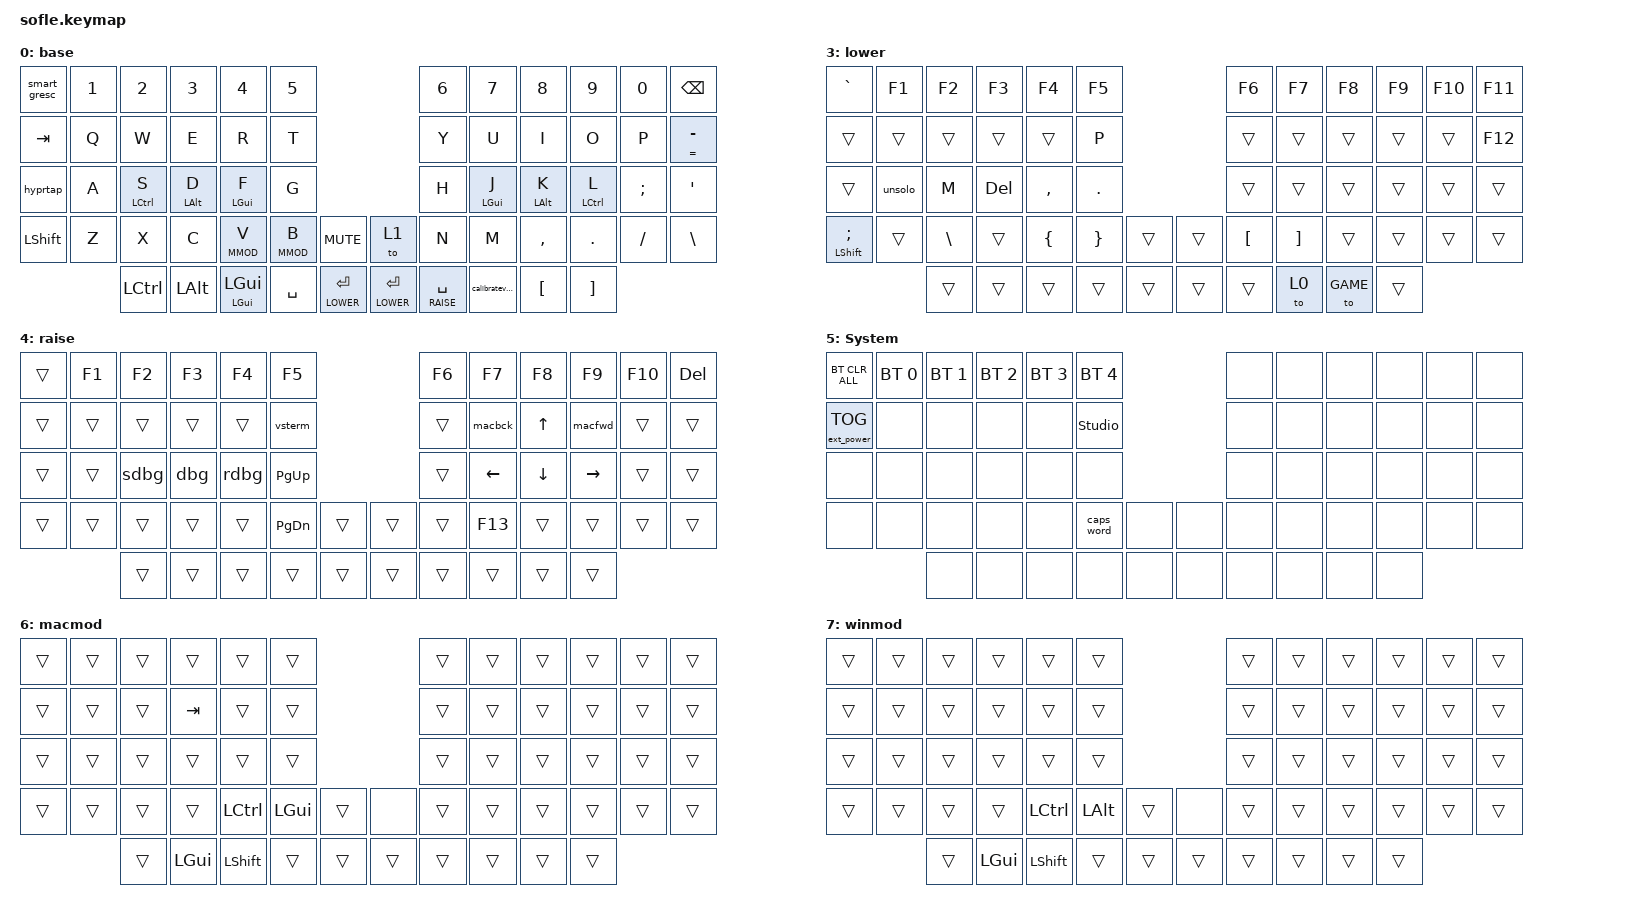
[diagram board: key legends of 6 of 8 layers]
/*
 * Copyright (c) 2020 The ZMK Contributors
 *
 * SPDX-License-Identifier: MIT
 */

#include <behaviors.dtsi>
#include <dt-bindings/zmk/bt.h>
#include <dt-bindings/zmk/ext_power.h>
#include <dt-bindings/zmk/keys.h>

// Encoders

&sensors { triggers-per-rotation = <30>; };

&left_encoder { steps = <60>; };

&right_encoder { steps = <60>; };

#define BASE 0
#define LOGIC 1
#define GAME 2
#define LOWER 3
#define RAISE 4
#define ADJUST 5
#define MMOD 6
#define WMOD 7

/ {
    // Activate ADJUST layer by pressing raise and lower

    conditional_layers {
        compatible = "zmk,conditional-layers";

        adjust_layer {
            if-layers = <LOWER RAISE>;
            then-layer = <ADJUST>;
        };
    };

    behaviors {
        th: taphold {
            compatible = "zmk,behavior-hold-tap";
            label = "TAP HOLD";
            #binding-cells = <2>;
            tapping-term-ms = <180>;
            quick-tap-ms = <120>;
            flavor = "tap-preferred";
            bindings = <&kp>, <&kp>;
        };

        pwr_tap: power_hold_tap {
            compatible = "zmk,behavior-hold-tap";
            label = "POWER_HOLD_TAP";
            #binding-cells = <2>;
            flavor = "hold-preferred";
            tapping-term-ms = <170>;
            bindings = <&pwr>, <&iterm>;
        };

        smart_gresc: smart_gresc {
            compatible = "zmk,behavior-mod-morph";
            label = "smart_gresc";
            #binding-cells = <0>;
            bindings = <&kp ESC>, <&sub_gresc>;

            mods = <(MOD_LGUI|MOD_LSFT)>;
            keep-mods = <(MOD_LGUI|MOD_LSFT)>;
        };

        sub_gresc: sub_gresc {
            compatible = "zmk,behavior-mod-morph";
            label = "sub_gresc";
            #binding-cells = <0>;
            bindings = <&kp GRAVE>, <&kp ESC>;

            mods = <(MOD_LALT|MOD_LCTL)>;
            keep-mods = <(MOD_LALT|MOD_LCTL)>;
        };

        slt: spacebar_layer_tap {
            compatible = "zmk,behavior-hold-tap";
            label = "SPACE_LAYER_TAP";
            #binding-cells = <2>;
            flavor = "tap-preferred";
            tapping-term-ms = <200>;
            quick-tap-ms = <125>;
            global-quick-tap;
            bindings = <&mo>, <&kp>;
        };

        tnpt: tab_numpad_tap {
            compatible = "zmk,behavior-hold-tap";
            label = "TAB_NUMPAD_TAP";
            #binding-cells = <2>;
            flavor = "tap-preferred";
            tapping-term-ms = <200>;
            quick-tap-ms = <135>;
            global-quick-tap;
            bindings = <&mo>, <&kp>;
        };

        hyprtap: hyper_tap_dance {
            compatible = "zmk,behavior-tap-dance";
            label = "HYPER_TAP_DANCE";
            #binding-cells = <0>;
            tapping-term-ms = <170>;
            bindings = <&hpr>, <&pwr_tap 0 0>;
        };

        glmt: gui_layer_mod_tap {
            compatible = "zmk,behavior-hold-tap";
            label = "GUI_LAYER_MOD_TAP";
            #binding-cells = <2>;
            flavor = "tap-preferred";
            tapping-term-ms = <200>;
            quick-tap-ms = <135>;
            global-quick-tap;
            bindings = <&glm>, <&kp>;
        };

        almt: alt_layer_mod_tap {
            compatible = "zmk,behavior-hold-tap";
            label = "ALT_LAYER_MOD_TAP";
            #binding-cells = <2>;
            flavor = "tap-preferred";
            tapping-term-ms = <200>;
            quick-tap-ms = <135>;
            global-quick-tap;
            bindings = <&alm>, <&kp>;
        };

        clmt: ctrl_layer_mod_tap {
            compatible = "zmk,behavior-hold-tap";
            label = "CTRL_LAYER_MOD_TAP";
            #binding-cells = <2>;
            flavor = "tap-preferred";
            tapping-term-ms = <200>;
            quick-tap-ms = <135>;
            global-quick-tap;
            bindings = <&clm>, <&kp>;
        };

        slmt: shft_layer_mod_tap {
            compatible = "zmk,behavior-hold-tap";
            label = "SHFT_LAYER_MOD_TAP";
            #binding-cells = <2>;
            flavor = "tap-preferred";
            tapping-term-ms = <200>;
            quick-tap-ms = <135>;
            global-quick-tap;
            bindings = <&slm>, <&kp>;
        };

        cmt: cust_mod_tap {
            compatible = "zmk,behavior-hold-tap";
            label = "CUST_MOD_TAP";
            #binding-cells = <2>;
            flavor = "tap-preferred";
            tapping-term-ms = <200>;
            quick-tap-ms = <135>;
            global-quick-tap;
            bindings = <&kp>, <&kp>;
        };
    };

    macros {
        hpr: hyper {
            label = "hyper";
            compatible = "zmk,behavior-macro";
            #binding-cells = <0>;
            wait-ms = <0>;
            bindings =
                <&macro_press>,
                <&kp LSHFT &kp LCTRL &kp LALT &kp LGUI>,
                <&macro_pause_for_release>,
                <&macro_release>,
                <&kp LSHFT &kp LCTRL &kp LALT &kp LGUI>;
        };

        pwr: powerclaw {
            label = "powerclaw";
            compatible = "zmk,behavior-macro";
            #binding-cells = <0>;
            wait-ms = <0>;
            bindings =
                <&macro_press>,
                <&kp LCTRL &kp LALT &kp LGUI>,
                <&macro_pause_for_release>,
                <&macro_release>,
                <&kp LCTRL &kp LALT &kp LGUI>;
        };

        meh: meh {
            label = "meh";
            compatible = "zmk,behavior-macro";
            #binding-cells = <0>;
            wait-ms = <0>;
            bindings =
                <&macro_press>,
                <&kp LSHFT &kp LCTRL &kp LALT &kp LGUI>,
                <&macro_pause_for_release>,
                <&macro_release>,
                <&kp LSHFT &kp LCTRL &kp LALT &kp LGUI>;
        };

        macbck: macbck {
            label = "macbck";
            compatible = "zmk,behavior-macro";
            #binding-cells = <0>;
            wait-ms = <10>;
            bindings =
                <&macro_press>,
                <&kp LGUI>,
                <&macro_tap>,
                <&kp LBKT>,
                <&macro_release>,
                <&kp LGUI>;
        };

        macfwd: macfwd {
            label = "macfwd";
            compatible = "zmk,behavior-macro";
            #binding-cells = <0>;
            wait-ms = <10>;
            bindings =
                <&macro_press>,
                <&kp LGUI>,
                <&macro_tap>,
                <&kp RBKT>,
                <&macro_release>,
                <&kp LGUI>;
        };

        iterm: iterm {
            label = "iterm";
            compatible = "zmk,behavior-macro";
            #binding-cells = <0>;
            wait-ms = <0>;
            bindings =
                <&macro_press>,
                <&kp LSHFT &kp LCTRL &kp LALT &kp LGUI>,
                <&macro_tap>,
                <&kp T>,
                <&macro_release>,
                <&kp LSHFT &kp LCTRL &kp LALT &kp LGUI>;
        };

        unsolo: unsolo {
            label = "unsolo";
            compatible = "zmk,behavior-macro";
            #binding-cells = <0>;
            wait-ms = <0>;
            bindings =
                <&macro_press>,
                <&kp LCTRL &kp LALT &kp LGUI>,
                <&macro_tap>,
                <&kp S>,
                <&macro_release>,
                <&kp LCTRL &kp LALT &kp LGUI>;
        };

        dbg: vscode_debug {
            label = "vscode_debug";
            compatible = "zmk,behavior-macro";
            #binding-cells = <0>;
            wait-ms = <0>;
            bindings = <&macro_tap>, <&kp F5>;
        };

        rdbg: restart_debug {
            label = "restart_debug";
            compatible = "zmk,behavior-macro";
            #binding-cells = <0>;
            wait-ms = <0>;
            bindings =
                <&macro_press>,
                <&kp LSHFT &kp LGUI>,
                <&macro_tap>,
                <&kp F5>,
                <&macro_release>,
                <&kp LSHFT &kp LGUI>;
        };

        sdbg: stop_debug {
            label = "stop_debug";
            compatible = "zmk,behavior-macro";
            #binding-cells = <0>;
            wait-ms = <0>;
            bindings =
                <&macro_press>,
                <&kp LSHFT>,
                <&macro_tap>,
                <&kp F5>,
                <&macro_release>,
                <&kp LSHFT>;
        };

        vsterm: vscode_terminal {
            label = "vscode_terminal";
            compatible = "zmk,behavior-macro";
            #binding-cells = <0>;
            wait-ms = <0>;
            bindings =
                <&macro_press>,
                <&kp LCTRL>,
                <&macro_tap>,
                <&kp GRAVE>,
                <&macro_release>,
                <&kp LCTRL>;
        };

        glm: glm {
            label = "GUI_LAYER_MOD";
            compatible = "zmk,behavior-macro-one-param";
            wait-ms = <0>;
            tap-ms = <0>;
            #binding-cells = <1>;
            bindings =
                <&macro_param_1to1>,
                <&macro_press>,
                <&mo MACRO_PLACEHOLDER>,
                <&macro_press>,
                <&kp LGUI>,
                <&macro_pause_for_release>,
                <&macro_param_1to1>,
                <&macro_release>,
                <&mo MACRO_PLACEHOLDER>,
                <&macro_release>,
                <&kp LGUI>;
        };

        alm: alm {
            label = "ALT_LAYER_MOD";
            compatible = "zmk,behavior-macro-one-param";
            wait-ms = <0>;
            tap-ms = <0>;
            #binding-cells = <1>;
            bindings =
                <&macro_param_1to1>,
                <&macro_press>,
                <&mo MACRO_PLACEHOLDER>,
                <&macro_press>,
                <&kp LALT>,
                <&macro_pause_for_release>,
                <&macro_param_1to1>,
                <&macro_release>,
                <&mo MACRO_PLACEHOLDER>,
                <&macro_release>,
                <&kp LALT>;
        };

        clm: clm {
            label = "CTRL_LAYER_MOD";
            compatible = "zmk,behavior-macro-one-param";
            wait-ms = <0>;
            tap-ms = <0>;
            #binding-cells = <1>;
            bindings =
                <&macro_param_1to1>,
                <&macro_press>,
                <&mo MACRO_PLACEHOLDER>,
                <&macro_press>,
                <&kp LCTRL>,
                <&macro_pause_for_release>,
                <&macro_param_1to1>,
                <&macro_release>,
                <&mo MACRO_PLACEHOLDER>,
                <&macro_release>,
                <&kp LCTRL>;
        };

        slm: slm {
            label = "SHFT_LAYER_MOD";
            compatible = "zmk,behavior-macro-one-param";
            wait-ms = <0>;
            tap-ms = <0>;
            #binding-cells = <1>;
            bindings =
                <&macro_param_1to1>,
                <&macro_press>,
                <&mo MACRO_PLACEHOLDER>,
                <&macro_press>,
                <&kp LSHFT>,
                <&macro_pause_for_release>,
                <&macro_param_1to1>,
                <&macro_release>,
                <&mo MACRO_PLACEHOLDER>,
                <&macro_release>,
                <&kp LSHFT>;
        };

        shiftcomma: shiftcomma {
            compatible = "zmk,behavior-macro";
            label = "SHIFTCOMMA";
            #binding-cells = <0>;
            wait-ms = <0>;
            bindings =
                <&macro_press>,
                <&kp LEFT_SHIFT>,
                <&macro_tap>,
                <&kp COMMA>,
                <&macro_release>,
                <&kp LEFT_SHIFT>;
        };

        shiftdot: shiftdot {
            compatible = "zmk,behavior-macro";
            label = "SHIFTDOT";
            #binding-cells = <0>;
            wait-ms = <0>;
            bindings =
                <&macro_press>,
                <&kp LEFT_SHIFT>,
                <&macro_tap>,
                <&kp PERIOD>,
                <&macro_release>,
                <&kp LEFT_SHIFT>;
        };

        calibrateview: calibrateview {
            compatible = "zmk,behavior-macro";
            #binding-cells = <0>;
            bindings = <&macro_press>, <&kp LC(LA(LG(C)))>, <&macro_release>;

            label = "CALIBRATEVIEW";
        };
    };

    keymap {
        compatible = "zmk,keymap";

        default_layer {
            label = "base";
            display-name = "base";
            bindings = <
&smart_gresc  &kp N1  &kp N2        &kp N3       &kp N4          &kp N5                                              &kp N6            &kp N7          &kp N8       &kp N9        &kp N0    &kp BSPC
&kp TAB       &kp Q   &kp W         &kp E        &kp R           &kp T                                               &kp Y             &kp U           &kp I        &kp O         &kp P     &th EQUAL MINUS
&hyprtap      &kp A   &cmt LCTRL S  &cmt LALT D  &cmt LGUI F     &kp G                                               &kp H             &cmt LGUI J     &cmt LALT K  &cmt LCTRL L  &kp SEMI  &kp SQT
&kp LSHFT     &kp Z   &kp X         &kp C        &clmt MMOD V    &glmt MMOD B  &kp C_MUTE          &to 1             &kp N             &kp M           &kp COMMA    &kp DOT       &kp FSLH  &kp BSLH
                      &kp LCTRL     &kp LALT     &cmt LGUI LGUI  &kp SPACE     &slt LOWER ENTER    &slt LOWER ENTER  &slt RAISE SPACE  &calibrateview  &kp LBKT     &kp RBKT
            >;

            sensor-bindings =
                <&inc_dec_kp C_VOL_UP C_VOL_DN>,
                <&inc_dec_kp C_VOL_UP C_VOL_DN>;
        };

        logic_layer {
            label = "logic";
            display-name = "logic";
            bindings = <
&trans  &trans  &trans  &trans  &trans  &trans                    &trans  &trans  &trans  &trans  &trans  &trans
&trans  &trans  &trans  &trans  &trans  &trans                    &trans  &trans  &trans  &trans  &trans  &trans
&trans  &trans  &trans  &trans  &trans  &trans                    &trans  &trans  &trans  &trans  &trans  &trans
&trans  &trans  &trans  &trans  &trans  &trans  &trans    &to 0   &trans  &trans  &trans  &trans  &trans  &trans
                &trans  &trans  &trans  &trans  &trans    &trans  &trans  &trans  &trans
            >;

            sensor-bindings =
                <&inc_dec_kp DOT COMMA>,
                <&inc_dec_kp C_VOL_UP C_VOL_DN>;
        };

        game_layer {
            label = "game";
            display-name = "game";
            bindings = <
&trans  &trans  &trans  &trans  &trans     &trans                    &trans  &trans  &trans  &trans  &trans  &trans
&trans  &trans  &trans  &trans  &trans     &trans                    &trans  &trans  &trans  &trans  &trans  &trans
&trans  &trans  &kp S   &kp D   &kp F      &trans                    &trans  &trans  &trans  &trans  &trans  &trans
&trans  &trans  &trans  &trans  &kp V      &kp B   &trans    &to 0   &trans  &trans  &trans  &trans  &trans  &trans
                &trans  &trans  &kp SPACE  &trans  &trans    &trans  &trans  &trans  &trans
            >;

            sensor-bindings =
                <&inc_dec_kp DOT COMMA>,
                <&inc_dec_kp C_VOL_UP C_VOL_DN>;
        };

        lower_layer {
            label = "lower";
            display-name = "lower";
            bindings = <
&kp GRAVE        &kp F1   &kp F2    &kp F3   &kp F4     &kp F5                      &kp F6    &kp F7    &kp F8    &kp F9  &kp F10  &kp F11
&trans           &trans   &trans    &trans   &trans     &kp P                       &trans    &trans    &trans    &trans  &trans   &kp F12
&trans           &unsolo  &kp M     &kp DEL  &kp COMMA  &kp DOT                     &trans    &trans    &trans    &trans  &trans   &trans
&cmt LSHFT SEMI  &trans   &kp BSLH  &trans   &kp LBRC   &kp RBRC  &trans    &trans  &kp LBKT  &kp RBKT  &trans    &trans  &trans   &trans
                          &trans    &trans   &trans     &trans    &trans    &trans  &trans    &to 0     &to GAME  &trans
            >;

            sensor-bindings =
                <&inc_dec_kp C_VOL_UP C_VOL_DN>,
                <&inc_dec_kp C_VOL_UP C_VOL_DN>;
        };

        raise_layer {
            label = "raise";
            display-name = "raise";
            bindings = <
&trans  &kp F1  &kp F2  &kp F3  &kp F4  &kp F5                       &kp F6  &kp F7    &kp F8    &kp F9     &kp F10  &kp DEL
&trans  &trans  &trans  &trans  &trans  &vsterm                      &trans  &macbck   &kp UP    &macfwd    &trans   &trans
&trans  &trans  &sdbg   &dbg    &rdbg   &kp PG_UP                    &trans  &kp LEFT  &kp DOWN  &kp RIGHT  &trans   &trans
&trans  &trans  &trans  &trans  &trans  &kp PG_DN  &trans    &trans  &trans  &kp F13   &trans    &trans     &trans   &trans
                &trans  &trans  &trans  &trans     &trans    &trans  &trans  &trans    &trans    &trans
            >;

            sensor-bindings = <&inc_dec_kp C_VOL_UP C_VOL_DN &inc_dec_kp PG_UP PG_DN>;
        };

        adjust_layer {
            // ----------------------------------------------------------------------------------------------------------------------------
            // | BTCLR  |  BT1    |  BT2    |   BT3   |   BT4   |   BT5   |                  |      |      |       |      |       |       |
            // | EXTPWR | RGB_HUD | RGB_HUI | RGB_SAD | RGB_SAI | RGB_EFF |                  |      |      |       |      |       |       |
            // |        | RGB_BRD | RGB_BRI |         |         |         |                  |      |      |       |      |       |       |
            // |        |         |         |         |         |         | RGB_TOG | |      |      |      |       |      |       |       |
            //                    |         |         |         |         |         | |      |      |      |       |      |

            display-name = "System";
            bindings = <
&bt BT_CLR_ALL     &bt BT_SEL 0  &bt BT_SEL 1  &bt BT_SEL 2  &bt BT_SEL 3  &bt BT_SEL 4                    &none  &none  &none  &none  &none  &none
&ext_power EP_TOG  &none         &none         &none         &none         &studio_unlock                  &none  &none  &none  &none  &none  &none
&none              &none         &none         &none         &none         &none                           &none  &none  &none  &none  &none  &none
&none              &none         &none         &none         &none         &caps_word      &none    &none  &none  &none  &none  &none  &none  &none
                                 &none         &none         &none         &none           &none    &none  &none  &none  &none  &none
            >;

            sensor-bindings = <&inc_dec_kp C_VOL_UP C_VOL_DN &inc_dec_kp PG_UP PG_DN>;
        };

        macmod_layer {
            label = "macmod";
            display-name = "macmod";
            bindings = <
&trans  &trans  &trans  &trans    &trans     &trans                      &trans  &trans  &trans  &trans  &trans  &trans
&trans  &trans  &trans  &kp TAB   &trans     &trans                      &trans  &trans  &trans  &trans  &trans  &trans
&trans  &trans  &trans  &trans    &trans     &trans                      &trans  &trans  &trans  &trans  &trans  &trans
&trans  &trans  &trans  &trans    &kp LCTRL  &kp LGUI  &trans    &none   &trans  &trans  &trans  &trans  &trans  &trans
                &trans  &kp LGUI  &kp LSHFT  &trans    &trans    &trans  &trans  &trans  &trans  &trans
            >;

            sensor-bindings = <&inc_dec_kp C_VOL_UP C_VOL_DN &inc_dec_kp PG_UP PG_DN>;
        };

        winmod_layer {
            label = "winmod";
            display-name = "winmod";
            bindings = <
&trans  &trans  &trans  &trans    &trans     &trans                      &trans  &trans  &trans  &trans  &trans  &trans
&trans  &trans  &trans  &trans    &trans     &trans                      &trans  &trans  &trans  &trans  &trans  &trans
&trans  &trans  &trans  &trans    &trans     &trans                      &trans  &trans  &trans  &trans  &trans  &trans
&trans  &trans  &trans  &trans    &kp LCTRL  &kp LALT  &trans    &none   &trans  &trans  &trans  &trans  &trans  &trans
                &trans  &kp LGUI  &kp LSHFT  &trans    &trans    &trans  &trans  &trans  &trans  &trans
            >;

            sensor-bindings = <&inc_dec_kp C_VOL_UP C_VOL_DN &inc_dec_kp PG_UP PG_DN>;
        };
    };
};
